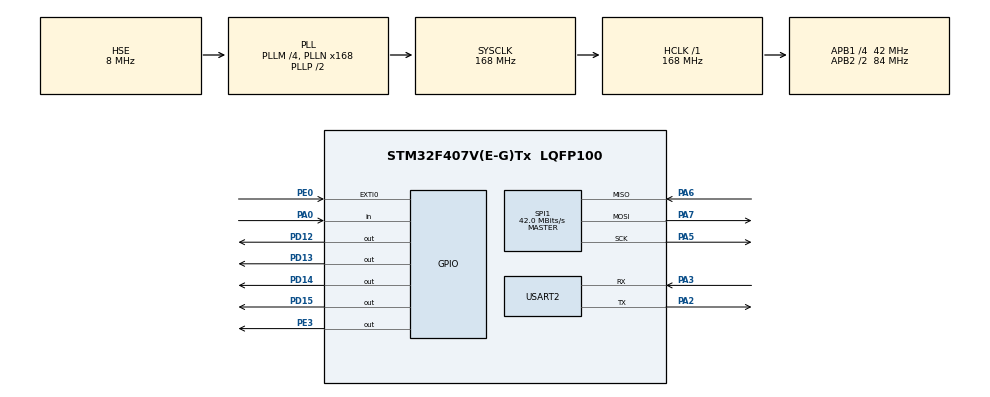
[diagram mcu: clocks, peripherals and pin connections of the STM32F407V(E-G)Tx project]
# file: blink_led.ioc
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Dma.Request0=USART2_RX
Dma.USART2_RX.0.Direction=DMA_PERIPH_TO_MEMORY
Dma.USART2_RX.0.FIFOMode=DMA_FIFOMODE_DISABLE
Dma.USART2_RX.0.Instance=DMA1_Stream5
Dma.USART2_RX.0.MemDataAlignment=DMA_MDATAALIGN_BYTE
Dma.USART2_RX.0.MemInc=DMA_MINC_ENABLE
Dma.USART2_RX.0.Mode=DMA_CIRCULAR
Dma.USART2_RX.0.PeriphDataAlignment=DMA_PDATAALIGN_BYTE
Dma.USART2_RX.0.PeriphInc=DMA_PINC_DISABLE
Dma.USART2_RX.0.Priority=DMA_PRIORITY_LOW
Mcu.Family=STM32F4
Mcu.Name=STM32F407V(E-G)Tx
Mcu.Package=LQFP100
NVIC.DMA1_Stream5_IRQn=true\:0\:0\:false\:false\:true\:false\:true\:true
NVIC.EXTI0_IRQn=true\:0\:0\:false\:false\:true\:true\:true\:true
NVIC.PriorityGroup=NVIC_PRIORITYGROUP_4
PA0-WKUP.Signal=GPIO_Input
PA13.Mode=Serial_Wire
PA13.Signal=SYS_JTMS-SWDIO
PA14.Mode=Serial_Wire
PA14.Signal=SYS_JTCK-SWCLK
PA2.Mode=Asynchronous
PA2.Signal=USART2_TX
PA3.Mode=Asynchronous
PA3.Signal=USART2_RX
PA5.Mode=Full_Duplex_Master
PA5.Signal=SPI1_SCK
PA6.Mode=Full_Duplex_Master
PA6.Signal=SPI1_MISO
PA7.Mode=Full_Duplex_Master
PA7.Signal=SPI1_MOSI
PD12.Signal=GPIO_Output
PD13.Signal=GPIO_Output
PD14.Signal=GPIO_Output
PD15.Signal=GPIO_Output
PE0.Signal=GPXTI0
PE3.PinState=GPIO_PIN_SET
PE3.Signal=GPIO_Output
PH0-OSC_IN.Mode=HSE-External-Oscillator
PH0-OSC_IN.Signal=RCC_OSC_IN
PH1-OSC_OUT.Mode=HSE-External-Oscillator
PH1-OSC_OUT.Signal=RCC_OSC_OUT
ProjectManager.HeapSize=0x200
ProjectManager.StackSize=0x400
ProjectManager.TargetToolchain=MDK-ARM V5.32
RCC.48MHZClocksFreq_Value=84000000
RCC.AHBFreq_Value=168000000
RCC.APB1CLKDivider=RCC_HCLK_DIV4
RCC.APB1Freq_Value=42000000
RCC.APB1TimFreq_Value=84000000
RCC.APB2CLKDivider=RCC_HCLK_DIV2
RCC.APB2Freq_Value=84000000
RCC.APB2TimFreq_Value=168000000
RCC.CortexFreq_Value=168000000
RCC.HCLKFreq_Value=168000000
RCC.HSE_VALUE=8000000
RCC.HSI_VALUE=16000000
RCC.LSE_VALUE=32768
RCC.PLLM=4
RCC.PLLN=168
RCC.PLLSourceVirtual=RCC_PLLSOURCE_HSE
RCC.SYSCLKFreq_VALUE=168000000
RCC.SYSCLKSource=RCC_SYSCLKSOURCE_PLLCLK
RCC.VCOOutputFreq_Value=336000000
SPI1.BaudRatePrescaler=SPI_BAUDRATEPRESCALER_2
SPI1.CalculateBaudRate=42.0 MBits/s
SPI1.Direction=SPI_DIRECTION_2LINES
SPI1.Mode=SPI_MODE_MASTER
SPI1.VirtualType=VM_MASTER
USART2.VirtualMode=VM_ASYNC
board=custom

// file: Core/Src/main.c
/* USER CODE BEGIN Header */
/**
  ******************************************************************************
  * @file           : main.c
  * @brief          : Main program body
  ******************************************************************************
  * @attention
  *
  * Copyright (c) 2023 STMicroelectronics.
  * All rights reserved.
  *
  * This software is licensed under terms that can be found in the LICENSE file
  * in the root directory of this software component.
  * If no LICENSE file comes with this software, it is provided AS-IS.
  *
  ******************************************************************************
  */
/* USER CODE END Header */
#include "main.h"

SPI_HandleTypeDef hspi1;

UART_HandleTypeDef huart2;
DMA_HandleTypeDef hdma_usart2_rx;

/* USER CODE BEGIN PV */
uint8_t spi_tx_buf[2], spi_rx_buf[2];

/* USER CODE END PV */

void SystemClock_Config(void);
static void MX_GPIO_Init(void);
static void MX_DMA_Init(void);
static void MX_USART2_UART_Init(void);
static void MX_SPI1_Init(void);

/* USER CODE BEGIN 0 */
GPIO_PinState btn_status;
char tx_data[10] = "hello\r\n";
char rx_data[10];
/* USER CODE END 0 */

int main(void)
{

  /* MCU Configuration--------------------------------------------------------*/

  /* Reset of all peripherals, Initializes the Flash interface and the Systick. */
  HAL_Init();

  /* Configure the system clock */
  SystemClock_Config();

  /* Initialize all configured peripherals */
  MX_GPIO_Init();
  MX_DMA_Init();
  MX_USART2_UART_Init();
  MX_SPI1_Init();
  /* USER CODE BEGIN 2 */
	HAL_UART_Receive_DMA(&huart2,(uint8_t *)rx_data,1);
  /* USER CODE END 2 */

	HAL_GPIO_WritePin(GPIOE, GPIO_PIN_3, GPIO_PIN_RESET);
	spi_tx_buf[0] = 0x20;
	spi_tx_buf[1] = 0x11;
	HAL_SPI_Transmit(&hspi1, spi_tx_buf, 2, 10); // 10 ms wait
	HAL_GPIO_WritePin(GPIOE, GPIO_PIN_3, GPIO_PIN_SET);
  /* Infinite loop */
	HAL_GPIO_WritePin(GPIOE, GPIO_PIN_3, GPIO_PIN_RESET);
	spi_tx_buf[0] = 0x20 | 0x80;
	HAL_SPI_Transmit(&hspi1, spi_tx_buf, 1, 10); // 10 ms
	HAL_SPI_Receive(&hspi1, spi_rx_buf, 1, 10); // 10 ms
	HAL_GPIO_WritePin(GPIOE, GPIO_PIN_3, GPIO_PIN_SET);
  while (1)
  {
		HAL_GPIO_WritePin(GPIOE, GPIO_PIN_3, GPIO_PIN_RESET);
		spi_tx_buf[0] = 0x29 | 0x80;
		HAL_SPI_Transmit(&hspi1, spi_tx_buf, 1, 10); // 10 ms
		HAL_SPI_Receive(&hspi1, spi_rx_buf, 1, 10); // 10 ms
		HAL_GPIO_WritePin(GPIOE, GPIO_PIN_3, GPIO_PIN_SET);
    /* USER CODE BEGIN 3 */

		HAL_Delay(300);
  }
  /* USER CODE END 3 */
}

void SystemClock_Config(void)
{
  RCC_OscInitTypeDef RCC_OscInitStruct = {0};
  RCC_ClkInitTypeDef RCC_ClkInitStruct = {0};

  /** Configure the main internal regulator output voltage
  */
  __HAL_RCC_PWR_CLK_ENABLE();
  __HAL_PWR_VOLTAGESCALING_CONFIG(PWR_REGULATOR_VOLTAGE_SCALE1);

  /** Initializes the RCC Oscillators according to the specified parameters
  * in the RCC_OscInitTypeDef structure.
  */
  RCC_OscInitStruct.OscillatorType = RCC_OSCILLATORTYPE_HSE;
  RCC_OscInitStruct.HSEState = RCC_HSE_ON;
  RCC_OscInitStruct.PLL.PLLState = RCC_PLL_ON;
  RCC_OscInitStruct.PLL.PLLSource = RCC_PLLSOURCE_HSE;
  RCC_OscInitStruct.PLL.PLLM = 4;
  RCC_OscInitStruct.PLL.PLLN = 168;
  RCC_OscInitStruct.PLL.PLLP = RCC_PLLP_DIV2;
  RCC_OscInitStruct.PLL.PLLQ = 4;
  if (HAL_RCC_OscConfig(&RCC_OscInitStruct) != HAL_OK)
  {
    Error_Handler();
  }

  /** Initializes the CPU, AHB and APB buses clocks
  */
  RCC_ClkInitStruct.ClockType = RCC_CLOCKTYPE_HCLK|RCC_CLOCKTYPE_SYSCLK
                              |RCC_CLOCKTYPE_PCLK1|RCC_CLOCKTYPE_PCLK2;
  RCC_ClkInitStruct.SYSCLKSource = RCC_SYSCLKSOURCE_PLLCLK;
  RCC_ClkInitStruct.AHBCLKDivider = RCC_SYSCLK_DIV1;
  RCC_ClkInitStruct.APB1CLKDivider = RCC_HCLK_DIV4;
  RCC_ClkInitStruct.APB2CLKDivider = RCC_HCLK_DIV2;

  if (HAL_RCC_ClockConfig(&RCC_ClkInitStruct, FLASH_LATENCY_5) != HAL_OK)
  {
    Error_Handler();
  }
}

static void MX_SPI1_Init(void)
{

  /* SPI1 parameter configuration*/
  hspi1.Instance = SPI1;
  hspi1.Init.Mode = SPI_MODE_MASTER;
  hspi1.Init.Direction = SPI_DIRECTION_2LINES;
  hspi1.Init.DataSize = SPI_DATASIZE_8BIT;
  hspi1.Init.CLKPolarity = SPI_POLARITY_LOW;
  hspi1.Init.CLKPhase = SPI_PHASE_1EDGE;
  hspi1.Init.NSS = SPI_NSS_SOFT;
  hspi1.Init.BaudRatePrescaler = SPI_BAUDRATEPRESCALER_2;
  hspi1.Init.FirstBit = SPI_FIRSTBIT_MSB;
  hspi1.Init.TIMode = SPI_TIMODE_DISABLE;
  hspi1.Init.CRCCalculation = SPI_CRCCALCULATION_DISABLE;
  hspi1.Init.CRCPolynomial = 10;
  if (HAL_SPI_Init(&hspi1) != HAL_OK)
  {
    Error_Handler();
  }

}

static void MX_USART2_UART_Init(void)
{

  huart2.Instance = USART2;
  huart2.Init.BaudRate = 115200;
  huart2.Init.WordLength = UART_WORDLENGTH_8B;
  huart2.Init.StopBits = UART_STOPBITS_1;
  huart2.Init.Parity = UART_PARITY_NONE;
  huart2.Init.Mode = UART_MODE_TX_RX;
  huart2.Init.HwFlowCtl = UART_HWCONTROL_NONE;
  huart2.Init.OverSampling = UART_OVERSAMPLING_16;
  if (HAL_UART_Init(&huart2) != HAL_OK)
  {
    Error_Handler();
  }

}

static void MX_DMA_Init(void)
{

  /* DMA controller clock enable */
  __HAL_RCC_DMA1_CLK_ENABLE();

  /* DMA interrupt init */
  /* DMA1_Stream5_IRQn interrupt configuration */
  HAL_NVIC_SetPriority(DMA1_Stream5_IRQn, 0, 0);
  HAL_NVIC_EnableIRQ(DMA1_Stream5_IRQn);

}

static void MX_GPIO_Init(void)
{
  GPIO_InitTypeDef GPIO_InitStruct = {0};

  /* GPIO Ports Clock Enable */
  __HAL_RCC_GPIOE_CLK_ENABLE();
  __HAL_RCC_GPIOH_CLK_ENABLE();
  __HAL_RCC_GPIOA_CLK_ENABLE();
  __HAL_RCC_GPIOD_CLK_ENABLE();

  /*Configure GPIO pin Output Level */
  HAL_GPIO_WritePin(GPIOE, GPIO_PIN_3, GPIO_PIN_SET);

  /*Configure GPIO pin Output Level */
  HAL_GPIO_WritePin(GPIOD, GPIO_PIN_12|GPIO_PIN_13|GPIO_PIN_14|GPIO_PIN_15, GPIO_PIN_RESET);

  /*Configure GPIO pin : PE3 */
  GPIO_InitStruct.Pin = GPIO_PIN_3;
  GPIO_InitStruct.Mode = GPIO_MODE_OUTPUT_PP;
  GPIO_InitStruct.Pull = GPIO_NOPULL;
  GPIO_InitStruct.Speed = GPIO_SPEED_FREQ_LOW;
  HAL_GPIO_Init(GPIOE, &GPIO_InitStruct);

  /*Configure GPIO pin : PA0 */
  GPIO_InitStruct.Pin = GPIO_PIN_0;
  GPIO_InitStruct.Mode = GPIO_MODE_INPUT;
  GPIO_InitStruct.Pull = GPIO_NOPULL;
  HAL_GPIO_Init(GPIOA, &GPIO_InitStruct);

  /*Configure GPIO pins : PD12 PD13 PD14 PD15 */
  GPIO_InitStruct.Pin = GPIO_PIN_12|GPIO_PIN_13|GPIO_PIN_14|GPIO_PIN_15;
  GPIO_InitStruct.Mode = GPIO_MODE_OUTPUT_PP;
  GPIO_InitStruct.Pull = GPIO_NOPULL;
  GPIO_InitStruct.Speed = GPIO_SPEED_FREQ_LOW;
  HAL_GPIO_Init(GPIOD, &GPIO_InitStruct);

  /*Configure GPIO pin : PE0 */
  GPIO_InitStruct.Pin = GPIO_PIN_0;
  GPIO_InitStruct.Mode = GPIO_MODE_IT_RISING;
  GPIO_InitStruct.Pull = GPIO_NOPULL;
  HAL_GPIO_Init(GPIOE, &GPIO_InitStruct);

  /* EXTI interrupt init*/
  HAL_NVIC_SetPriority(EXTI0_IRQn, 0, 0);
  HAL_NVIC_EnableIRQ(EXTI0_IRQn);

}

/* USER CODE BEGIN 4 */
// Recieve complete callback
void HAL_UART_RxCpltCallback(UART_HandleTypeDef *huart)
{
  /* Prevent unused argument(s) compilation warning */
  UNUSED(huart);
  /* NOTE: This function should not be modified, when the callback is needed,
           the HAL_UART_RxCpltCallback could be implemented in the user file
   */
	HAL_UART_Transmit(&huart2,(uint8_t *)rx_data, strlen(rx_data),1);
}

/* USER CODE END 4 */

void Error_Handler(void)
{
  __disable_irq();
  while (1)
  {
  }
}
